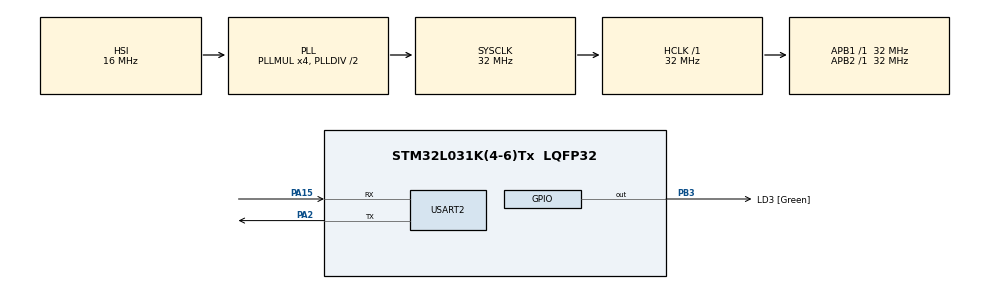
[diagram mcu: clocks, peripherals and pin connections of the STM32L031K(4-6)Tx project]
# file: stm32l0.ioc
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FREERTOS.HEAP_NUMBER=3
FREERTOS.INCLUDE_vTaskDelayUntil=1
FREERTOS.Tasks01=Task10ms,0,128,stm32_Task_10ms,Default,NULL,Dynamic,NULL,NULL
FREERTOS.configGENERATE_RUN_TIME_STATS=1
FREERTOS.configMINIMAL_STACK_SIZE=64
FREERTOS.configUSE_NEWLIB_REENTRANT=1
FREERTOS.configUSE_STATS_FORMATTING_FUNCTIONS=1
FREERTOS.configUSE_TIMERS=1
FREERTOS.configUSE_TRACE_FACILITY=1
Mcu.Family=STM32L0
Mcu.Name=STM32L031K(4-6)Tx
Mcu.Package=LQFP32
Mcu.UserConstants=TASK_PERIOD_10ms,10
PA13.GPIO_Label=TMS
PA13.Mode=Serial_Wire
PA13.Signal=SYS_SWDIO
PA14.Mode=Serial_Wire
PA14.Signal=SYS_SWCLK
PA15.GPIO_ModeDefaultPP=GPIO_MODE_AF_PP
PA15.GPIO_PuPd=GPIO_NOPULL
PA15.GPIO_Speed=GPIO_SPEED_FREQ_VERY_HIGH
PA15.Mode=Asynchronous
PA15.Signal=USART2_RX
PA2.Mode=Asynchronous
PA2.Signal=USART2_TX
PB3.GPIO_Label=LD3 [Green]
PB3.Signal=GPIO_Output
PC14-OSC32_IN.Mode=LSE-External-Oscillator
PC14-OSC32_IN.Signal=RCC_OSC32_IN
PC15-OSC32_OUT.Mode=LSE-External-Oscillator
PC15-OSC32_OUT.Signal=RCC_OSC32_OUT
ProjectManager.HeapSize=0x200
ProjectManager.StackSize=0x400
ProjectManager.TargetToolchain=STM32CubeIDE
RCC.AHBFreq_Value=32000000
RCC.APB1Freq_Value=32000000
RCC.APB1TimFreq_Value=32000000
RCC.APB2Freq_Value=32000000
RCC.APB2TimFreq_Value=32000000
RCC.HCLKFreq_Value=32000000
RCC.HSE_VALUE=8000000
RCC.HSI16_VALUE=16000000
RCC.HSI48_VALUE=48000000
RCC.HSI_VALUE=16000000
RCC.MSI_VALUE=2097000
RCC.PLLMUL=RCC_PLLMUL_4
RCC.SYSCLKFreq_VALUE=32000000
RCC.SYSCLKSource=RCC_SYSCLKSOURCE_PLLCLK
RCC.VCOOutputFreq_Value=64000000
USART2.VirtualMode-Asynchronous=VM_ASYNC
VP_FREERTOS_VS_CMSIS_V1.Mode=CMSIS_V1
board=NUCLEO-L031K6

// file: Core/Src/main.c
/* USER CODE BEGIN Header */
/**
  ******************************************************************************
  * @file           : main.c
  * @brief          : Main program body
  ******************************************************************************
  * @attention
  *
  * Copyright (c) 2023 STMicroelectronics.
  * All rights reserved.
  *
  * This software is licensed under terms that can be found in the LICENSE file
  * in the root directory of this software component.
  * If no LICENSE file comes with this software, it is provided AS-IS.
  *
  ******************************************************************************
  */
/* USER CODE END Header */
#include "main.h"
#include "cmsis_os.h"

/* USER CODE BEGIN Includes */
#include "bsp.h"

#include <stdio.h>
/* USER CODE END Includes */

UART_HandleTypeDef huart2;

osThreadId Task10msHandle;
/* USER CODE BEGIN PV */
static int count = 0;
/* USER CODE END PV */

void SystemClock_Config(void);
static void MX_GPIO_Init(void);
static void MX_USART2_UART_Init(void);
void stm32_Task_10ms(void const * argument);

int main(void)
{

  /* MCU Configuration--------------------------------------------------------*/

  /* Reset of all peripherals, Initializes the Flash interface and the Systick. */
  HAL_Init();

  /* Configure the system clock */
  SystemClock_Config();

  /* Initialize all configured peripherals */
  // MX_GPIO_Init();
  MX_USART2_UART_Init();

  /* Create the thread(s) */
  /* definition and creation of Task10ms */
  osThreadDef(Task10ms, stm32_Task_10ms, osPriorityNormal, 0, 128);
  Task10msHandle = osThreadCreate(osThread(Task10ms), NULL);

  /* Start scheduler */
  osKernelStart();
  /* We should never get here as control is now taken by the scheduler */
  /* Infinite loop */
  while (1)
  {

  }
}

void SystemClock_Config(void)
{
  RCC_OscInitTypeDef RCC_OscInitStruct = {0};
  RCC_ClkInitTypeDef RCC_ClkInitStruct = {0};
  RCC_PeriphCLKInitTypeDef PeriphClkInit = {0};

  /** Configure the main internal regulator output voltage
  */
  __HAL_PWR_VOLTAGESCALING_CONFIG(PWR_REGULATOR_VOLTAGE_SCALE1);

  /** Initializes the RCC Oscillators according to the specified parameters
  * in the RCC_OscInitTypeDef structure.
  */
  RCC_OscInitStruct.OscillatorType = RCC_OSCILLATORTYPE_HSI;
  RCC_OscInitStruct.HSIState = RCC_HSI_ON;
  RCC_OscInitStruct.HSICalibrationValue = RCC_HSICALIBRATION_DEFAULT;
  RCC_OscInitStruct.PLL.PLLState = RCC_PLL_ON;
  RCC_OscInitStruct.PLL.PLLSource = RCC_PLLSOURCE_HSI;
  RCC_OscInitStruct.PLL.PLLMUL = RCC_PLLMUL_4;
  RCC_OscInitStruct.PLL.PLLDIV = RCC_PLLDIV_2;
  if (HAL_RCC_OscConfig(&RCC_OscInitStruct) != HAL_OK)
  {
    Error_Handler();
  }

  /** Initializes the CPU, AHB and APB buses clocks
  */
  RCC_ClkInitStruct.ClockType = RCC_CLOCKTYPE_HCLK|RCC_CLOCKTYPE_SYSCLK
                              |RCC_CLOCKTYPE_PCLK1|RCC_CLOCKTYPE_PCLK2;
  RCC_ClkInitStruct.SYSCLKSource = RCC_SYSCLKSOURCE_PLLCLK;
  RCC_ClkInitStruct.AHBCLKDivider = RCC_SYSCLK_DIV1;
  RCC_ClkInitStruct.APB1CLKDivider = RCC_HCLK_DIV1;
  RCC_ClkInitStruct.APB2CLKDivider = RCC_HCLK_DIV1;

  if (HAL_RCC_ClockConfig(&RCC_ClkInitStruct, FLASH_LATENCY_1) != HAL_OK)
  {
    Error_Handler();
  }
  PeriphClkInit.PeriphClockSelection = RCC_PERIPHCLK_USART2;
  PeriphClkInit.Usart2ClockSelection = RCC_USART2CLKSOURCE_PCLK1;
  if (HAL_RCCEx_PeriphCLKConfig(&PeriphClkInit) != HAL_OK)
  {
    Error_Handler();
  }
}

static void MX_USART2_UART_Init(void)
{

  huart2.Instance = USART2;
  huart2.Init.BaudRate = 115200;
  huart2.Init.WordLength = UART_WORDLENGTH_8B;
  huart2.Init.StopBits = UART_STOPBITS_1;
  huart2.Init.Parity = UART_PARITY_NONE;
  huart2.Init.Mode = UART_MODE_TX_RX;
  huart2.Init.HwFlowCtl = UART_HWCONTROL_NONE;
  huart2.Init.OverSampling = UART_OVERSAMPLING_16;
  huart2.Init.OneBitSampling = UART_ONE_BIT_SAMPLE_DISABLE;
  huart2.AdvancedInit.AdvFeatureInit = UART_ADVFEATURE_NO_INIT;
  if (HAL_UART_Init(&huart2) != HAL_OK)
  {
    Error_Handler();
  }

}

#pragma GCC diagnostic push
#pragma GCC diagnostic ignored "-Wunused-function"
static void MX_GPIO_Init(void)
{
  GPIO_InitTypeDef GPIO_InitStruct = {0};

  /* GPIO Ports Clock Enable */
  __HAL_RCC_GPIOC_CLK_ENABLE();
  __HAL_RCC_GPIOA_CLK_ENABLE();
  __HAL_RCC_GPIOB_CLK_ENABLE();

  /*Configure GPIO pin Output Level */
  HAL_GPIO_WritePin(LD3_GPIO_Port, LD3_Pin, GPIO_PIN_RESET);

  /*Configure GPIO pin : LD3_Pin */
  GPIO_InitStruct.Pin = LD3_Pin;
  GPIO_InitStruct.Mode = GPIO_MODE_OUTPUT_PP;
  GPIO_InitStruct.Pull = GPIO_NOPULL;
  GPIO_InitStruct.Speed = GPIO_SPEED_FREQ_LOW;
  HAL_GPIO_Init(LD3_GPIO_Port, &GPIO_InitStruct);

}
#pragma GCC diagnostic pop

void stm32_Task_10ms(void const * argument)
{
  /* USER CODE BEGIN 5 */
	(void)argument;
  /* Infinite loop */
  for(;;)
  {
    count++;
    if((count%10) == 0)
    {
      BSP_DebugPrint("count = %d", (count/10));

    }

    if((count%100) == 0)
    {
      static int toggle_cnt = 0;
      BSP_LED_Toggle();
      BSP_DebugPrint("Toggle count: %d", toggle_cnt);
      toggle_cnt++;
    }

    osDelay(TASK_PERIOD_10ms);
  }
  /* USER CODE END 5 */
}

void Error_Handler(void)
{
  __disable_irq();
  while (1)
  {
  }
}

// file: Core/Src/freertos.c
/* USER CODE BEGIN Header */
/**
  ******************************************************************************
  * File Name          : freertos.c
  * Description        : Code for freertos applications
  ******************************************************************************
  * @attention
  *
  * Copyright (c) 2023 STMicroelectronics.
  * All rights reserved.
  *
  * This software is licensed under terms that can be found in the LICENSE file
  * in the root directory of this software component.
  * If no LICENSE file comes with this software, it is provided AS-IS.
  *
  ******************************************************************************
  */
/* USER CODE END Header */

#include "FreeRTOS.h"
#include "task.h"
#include "main.h"

/* GetIdleTaskMemory prototype (linked to static allocation support) */
void vApplicationGetIdleTaskMemory( StaticTask_t **ppxIdleTaskTCBBuffer, StackType_t **ppxIdleTaskStackBuffer, uint32_t *pulIdleTaskStackSize );

/* GetTimerTaskMemory prototype (linked to static allocation support) */
void vApplicationGetTimerTaskMemory( StaticTask_t **ppxTimerTaskTCBBuffer, StackType_t **ppxTimerTaskStackBuffer, uint32_t *pulTimerTaskStackSize );

/* Hook prototypes */
void configureTimerForRunTimeStats(void);
unsigned long getRunTimeCounterValue(void);

/* USER CODE BEGIN 1 */
/* Functions needed when configGENERATE_RUN_TIME_STATS is on */
__weak void configureTimerForRunTimeStats(void)
{

}

__weak unsigned long getRunTimeCounterValue(void)
{
return 0;
}
/* USER CODE END 1 */

/* USER CODE BEGIN GET_IDLE_TASK_MEMORY */
static StaticTask_t xIdleTaskTCBBuffer;
static StackType_t xIdleStack[configMINIMAL_STACK_SIZE];

void vApplicationGetIdleTaskMemory( StaticTask_t **ppxIdleTaskTCBBuffer, StackType_t **ppxIdleTaskStackBuffer, uint32_t *pulIdleTaskStackSize )
{
  *ppxIdleTaskTCBBuffer = &xIdleTaskTCBBuffer;
  *ppxIdleTaskStackBuffer = &xIdleStack[0];
  *pulIdleTaskStackSize = configMINIMAL_STACK_SIZE;
  /* place for user code */
}
/* USER CODE END GET_IDLE_TASK_MEMORY */

/* USER CODE BEGIN GET_TIMER_TASK_MEMORY */
static StaticTask_t xTimerTaskTCBBuffer;
static StackType_t xTimerStack[configTIMER_TASK_STACK_DEPTH];

void vApplicationGetTimerTaskMemory( StaticTask_t **ppxTimerTaskTCBBuffer, StackType_t **ppxTimerTaskStackBuffer, uint32_t *pulTimerTaskStackSize )
{
  *ppxTimerTaskTCBBuffer = &xTimerTaskTCBBuffer;
  *ppxTimerTaskStackBuffer = &xTimerStack[0];
  *pulTimerTaskStackSize = configTIMER_TASK_STACK_DEPTH;
  /* place for user code */
}
/* USER CODE END GET_TIMER_TASK_MEMORY */
